# Cortex_M7 register map
Vendor: Arm Ltd.; Series: ARMv7E-M; File version: 1.0.0
CPU: CM7 r0p0, little endian, MPU, FPU, double-precision FPU, DSP, 8 interrupt priority bits
Registers are 32-bit, read-write, reset 0x0 unless marked. A register's access mark holds for its fields unless they carry their own. Offsets are from the block's base; [hi:lo] are bit positions.

## FPU — Floating-Point Unit control: context control (lazy stacking, automatic state preservation), the lazy-stacking frame address, the default FPSCR and the VFP/MVE feature registers. Enable the FPU through SCB.CPACR (CP10/CP11) before use.
Base 0xE000EF30
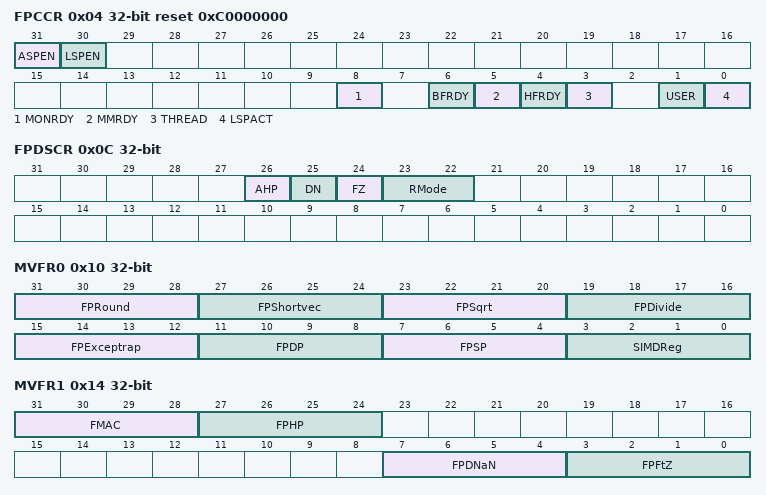
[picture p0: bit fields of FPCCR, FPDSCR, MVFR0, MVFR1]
0x04 FPCCR reset 0xC0000000 — Floating-Point Context Control Register: automatic and lazy FP state preservation on exception entry, and which exceptions may be taken while a lazy save is pending.
  [31] ASPEN — Automatic state preservation enable: 1 = executing an FP instruction sets CONTROL.FPCA, so the next exception entry uses the extended (FP) stack frame. Default 1.
  [30] LSPEN — Lazy state preservation enable: 1 = on exception entry only space is reserved for S0-S15/FPSCR and the registers are saved only if the handler uses the FPU (default, saves ~17 cycles); 0 = always saved.
  [8] MONRDY — DebugMonitor ready: 1 = the monitor exception can be taken during the lazy save.
  [6] BFRDY — BusFault ready: 1 = BusFault can be taken during the lazy save.
  [5] MMRDY — MemManage ready: 1 = MemManage can be taken during the lazy save (it was enabled and of sufficient priority).
  [4] HFRDY — HardFault ready: 1 = the priority when the frame was reserved allows HardFault to be taken during the lazy save.
  [3] THREAD — The reserved FP frame was allocated in Thread mode.
  [1] USER — The reserved FP frame belongs to unprivileged (user) code.
  [0] LSPACT — Lazy state preservation active: an FP context frame is reserved at FPCAR but the registers have not been saved yet. The first FP instruction in the handler triggers the save.
0x08 FPCAR — Floating-Point Context Address Register: location of the unpopulated FP register space (S0-S15, FPSCR) in the exception stack frame while FPCCR.LSPACT is set.
  [31:3] ADDRESS — Address of the unpopulated S0-S15/FPSCR area in the exception stack frame (8-byte aligned), valid while FPCCR.LSPACT is 1.
0x0C FPDSCR — Floating-Point Default Status Control Register: the FPSCR mode bits (rounding, flush-to-zero, default NaN, alternative half-precision) loaded on exception entry / when a new FP context starts.
  [26] AHP — Alternative half-precision: 1 = use the Arm alternative half-precision format (no infinities/NaNs) for conversions.
  [25] DN — Default NaN mode: 1 = any NaN result is the default NaN rather than propagating the input NaN.
  [24] FZ — Default flush-to-zero mode: 1 = denormals are flushed to zero (not IEEE compliant, faster on some cores).
  [23:22] RMode — Default rounding mode: 0 = round to nearest, 1 = towards +infinity, 2 = towards -infinity, 3 = towards zero.
    0=RN (Round to nearest); 1=RP (Round towards plus infinity); 2=RM (Round towards minus infinity); 3=RZ (Round towards zero)
0x10 MVFR0 ro — Media and VFP Feature Register 0: register bank size, single/double precision, divide, square root and rounding support. Read-only.
  [31:28] FPRound — Rounding modes: 1 = all IEEE 754 rounding modes supported.
  [27:24] FPShortvec — Short vector mode: 0 = not supported.
  [23:20] FPSqrt — VSQRT supported: 1 = yes.
  [19:16] FPDivide — VDIV supported: 1 = yes.
  [15:12] FPExceptrap — Floating-point exception trapping: 0 = not supported (Cortex-M FPUs never trap; the cumulative FPSCR flags are set).
  [11:8] FPDP — Double-precision support: 0 = none, 2 = supported (Cortex-M7 with the DP option, Cortex-M55/M85).
  [7:4] FPSP — Single-precision support: 0 = none, 2 = supported (VFPv3/FPv4/FPv5 level).
  [3:0] SIMDReg — Register bank: 0x1 = 16 double-precision (S0-S31) registers, 0x2 = 32 double-precision registers.
0x14 MVFR1 ro — Media and VFP Feature Register 1: flush-to-zero, default NaN, half-precision, fused MAC and (ARMv8.1-M) MVE support. Read-only.
  [31:28] FMAC — Fused multiply-accumulate (VFMA/VFMS/VFNMA/VFNMS): 1 = supported.
  [27:24] FPHP — Half-precision conversions: 1 = single<->half, 2 = also double<->half, 3 = full half-precision arithmetic.
  [7:4] FPDNaN — Default NaN mode: 1 = supported (FPSCR.DN).
  [3:0] FPFtZ — Flush-to-zero mode: 1 = supported (FPSCR.FZ).
0x18 MVFR2 ro — Media and VFP Feature Register 2: miscellaneous FPv5 features (VSEL, VCVT rounding variants, VRINT, VMAXNM/VMINNM). Read-only.
  [7:4] FPMisc — Miscellaneous FPv5 features: 0x4 = VSEL, VCVTA/N/P/M, VRINT*, VMAXNM/VMINNM supported.
